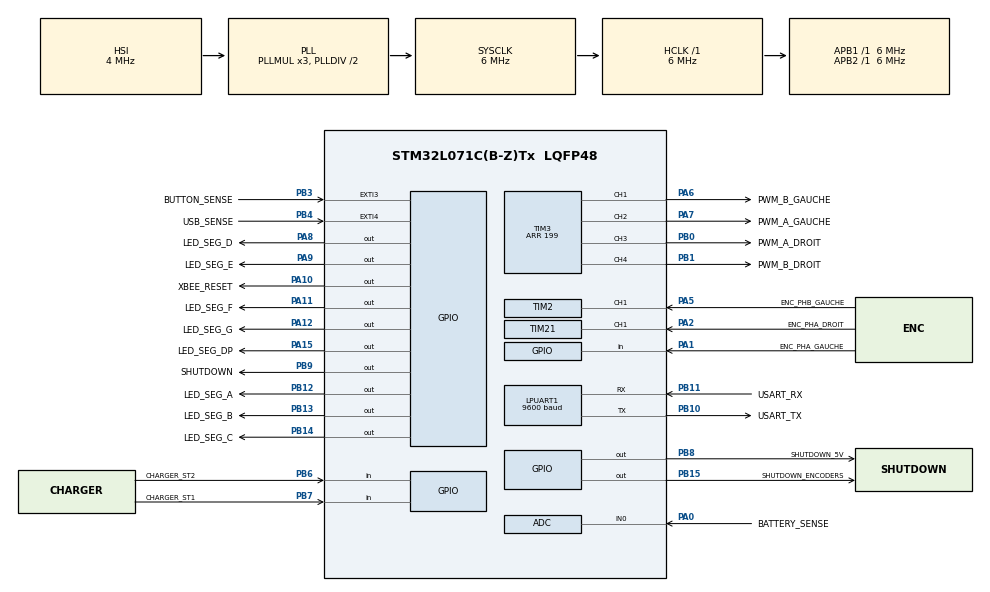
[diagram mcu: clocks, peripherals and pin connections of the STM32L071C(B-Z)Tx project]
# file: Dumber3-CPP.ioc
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ADC.Resolution=ADC_RESOLUTION_8B
ADC.SamplingTime=ADC_SAMPLETIME_160CYCLES_5
FREERTOS.INCLUDE_pcTaskGetTaskName=1
FREERTOS.INCLUDE_xEventGroupSetBitFromISR=1
FREERTOS.INCLUDE_xTaskAbortDelay=1
FREERTOS.INCLUDE_xTaskGetCurrentTaskHandle=1
FREERTOS.INCLUDE_xTaskGetHandle=1
FREERTOS.Tasks01=defaultTask,24,128,StartDefaultTask,Default,NULL,Dynamic,NULL,NULL
FREERTOS.configMAX_TASK_NAME_LEN=25
FREERTOS.configTICK_RATE_HZ=1000
FREERTOS.configTIMER_TASK_PRIORITY=3
FREERTOS.configTOTAL_HEAP_SIZE=1024
FREERTOS.configUSE_NEWLIB_REENTRANT=1
FREERTOS.configUSE_TICKLESS_IDLE=1
LPUART1.BaudRate=9600
LPUART1.DMADisableonRxErrorParam=UART_ADVFEATURE_DMA_DISABLEONRXERROR
LPUART1.WordLength=UART_WORDLENGTH_8B
Mcu.Family=STM32L0
Mcu.Name=STM32L071C(B-Z)Tx
Mcu.Package=LQFP48
NVIC.ADC1_COMP_IRQn=true\:3\:0\:false\:false\:true\:true\:true\:true\:true
NVIC.EXTI2_3_IRQn=true\:3\:0\:false\:false\:true\:true\:true\:true\:true
NVIC.EXTI4_15_IRQn=true\:3\:0\:false\:false\:true\:true\:true\:true\:true
NVIC.LPUART1_IRQn=true\:3\:0\:true\:false\:true\:true\:true\:true\:true
NVIC.TIM21_IRQn=true\:1\:0\:true\:false\:true\:false\:true\:true\:true
NVIC.TIM2_IRQn=true\:1\:0\:true\:false\:true\:false\:true\:true\:true
NVIC.TIM6_IRQn=true\:3\:0\:true\:false\:true\:false\:false\:true\:true
NVIC.TimeBase=TIM6_IRQn
NVIC.TimeBaseIP=TIM6
PA0.GPIO_Label=BATTERY_SENSE
PA0.Mode=IN0
PA0.Signal=ADC_IN0
PA1.GPIO_Label=ENC_PHA_GAUCHE
PA1.Signal=GPIO_Input
PA10.GPIO_Label=XBEE_RESET
PA10.PinState=GPIO_PIN_RESET
PA10.Signal=GPIO_Output
PA11.GPIO_Label=LED_SEG_F
PA11.Signal=GPIO_Output
PA12.GPIO_Label=LED_SEG_G
PA12.Signal=GPIO_Output
PA13.Mode=Serial_Wire
PA13.Signal=SYS_SWDIO
PA14.Mode=Serial_Wire
PA14.Signal=SYS_SWCLK
PA15.GPIO_Label=LED_SEG_DP
PA15.Signal=GPIO_Output
PA2.GPIO_Label=ENC_PHA_DROIT
PA2.Signal=S_TIM21_CH1
PA5.GPIO_Label=ENC_PHB_GAUCHE
PA5.Signal=S_TIM2_CH1
PA6.GPIO_Label=PWM_B_GAUCHE
PA6.Signal=S_TIM3_CH1
PA7.GPIO_Label=PWM_A_GAUCHE
PA7.Signal=S_TIM3_CH2
PA8.GPIO_Label=LED_SEG_D
PA8.Signal=GPIO_Output
PA9.GPIO_Label=LED_SEG_E
PA9.Signal=GPIO_Output
PB0.GPIO_Label=PWM_A_DROIT
PB0.GPIO_Speed=GPIO_SPEED_FREQ_LOW
PB0.Signal=S_TIM3_CH3
PB1.GPIO_Label=PWM_B_DROIT
PB1.GPIO_Speed=GPIO_SPEED_FREQ_LOW
PB1.Signal=S_TIM3_CH4
PB10.GPIO_Label=USART_TX
PB10.GPIO_Speed=GPIO_SPEED_FREQ_LOW
PB10.Mode=Asynchronous
PB10.Signal=LPUART1_TX
PB11.GPIO_Label=USART_RX
PB11.GPIO_Speed=GPIO_SPEED_FREQ_LOW
PB11.Mode=Asynchronous
PB11.Signal=LPUART1_RX
PB12.GPIO_Label=LED_SEG_A
PB12.GPIO_Speed=GPIO_SPEED_FREQ_LOW
PB12.PinState=GPIO_PIN_RESET
PB12.Signal=GPIO_Output
PB13.GPIO_Label=LED_SEG_B
PB13.GPIO_Speed=GPIO_SPEED_FREQ_LOW
PB13.Signal=GPIO_Output
PB14.GPIO_Label=LED_SEG_C
PB14.GPIO_Speed=GPIO_SPEED_FREQ_LOW
PB14.Signal=GPIO_Output
PB15.GPIO_Label=SHUTDOWN_ENCODERS
PB15.PinState=GPIO_PIN_SET
PB15.Signal=GPIO_Output
PB3.GPIO_Label=BUTTON_SENSE
PB3.GPIO_ModeDefaultEXTI=GPIO_MODE_IT_FALLING
PB3.Signal=GPXTI3
PB4.GPIO_Label=USB_SENSE
PB4.GPIO_ModeDefaultEXTI=GPIO_MODE_IT_RISING_FALLING
PB4.Signal=GPXTI4
PB6.GPIO_Label=CHARGER_ST2
PB6.Signal=GPIO_Input
PB7.GPIO_Label=CHARGER_ST1
PB7.Signal=GPIO_Input
PB8.GPIO_Label=SHUTDOWN_5V
PB8.Signal=GPIO_Output
PB9.GPIO_Label=SHUTDOWN
PB9.GPIO_ModeDefaultOutputPP=GPIO_MODE_OUTPUT_OD
PB9.PinState=GPIO_PIN_SET
PB9.Signal=GPIO_Output
ProjectManager.HeapSize=0x0
ProjectManager.StackSize=0x200
ProjectManager.TargetToolchain=STM32CubeIDE
RCC.ADCFreq_Value=4000000
RCC.AHBFreq_Value=6000000
RCC.APB1Freq_Value=6000000
RCC.APB1TimFreq_Value=6000000
RCC.APB2Freq_Value=6000000
RCC.APB2TimFreq_Value=6000000
RCC.HCLKFreq_Value=6000000
RCC.HSE_VALUE=8000000
RCC.HSI16_VALUE=16000000
RCC.HSIRCDiv=4
RCC.HSI_VALUE=4000000
RCC.LSE_VALUE=32768
RCC.MSI_VALUE=2097000
RCC.SYSCLKFreq_VALUE=6000000
RCC.SYSCLKSource=RCC_SYSCLKSOURCE_PLLCLK
RCC.VCOOutputFreq_Value=12000000
SH.S_TIM21_CH1.0=TIM21_CH1,PWM_Input_1
SH.S_TIM2_CH1.0=TIM2_CH1,PWM_Input_1
SH.S_TIM3_CH1.0=TIM3_CH1,PWM Generation1 CH1
SH.S_TIM3_CH2.0=TIM3_CH2,PWM Generation2 CH2
SH.S_TIM3_CH3.0=TIM3_CH3,PWM Generation3 CH3
SH.S_TIM3_CH4.0=TIM3_CH4,PWM Generation4 CH4
TIM2.ICFilter_1=3
TIM2.ICFilter_2=3
TIM2.Prescaler=0
TIM21.ICFilter_1=3
TIM21.ICFilter_2=3
TIM21.Prescaler=0
TIM3.Channel-PWM\ Generation1\ CH1=TIM_CHANNEL_1
TIM3.Channel-PWM\ Generation2\ CH2=TIM_CHANNEL_2
TIM3.Channel-PWM\ Generation3\ CH3=TIM_CHANNEL_3
TIM3.Channel-PWM\ Generation4\ CH4=TIM_CHANNEL_4
TIM3.Period=199
VP_FREERTOS_VS_CMSIS_V2.Mode=CMSIS_V2
VP_SYS_VS_tim6.Mode=TIM6
VP_TIM21_VS_ClockSourceINT.Mode=Internal
VP_TIM2_VS_ClockSourceINT.Mode=Internal
VP_TIM3_VS_ClockSourceINT.Mode=Internal
board=custom

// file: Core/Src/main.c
/* USER CODE BEGIN Header */
/**
  ******************************************************************************
  * @file           : main.c
  * @brief          : Main program body
  ******************************************************************************
  * @attention
  *
  * Copyright (c) 2026 STMicroelectronics.
  * All rights reserved.
  *
  * This software is licensed under terms that can be found in the LICENSE file
  * in the root directory of this software component.
  * If no LICENSE file comes with this software, it is provided AS-IS.
  *
  ******************************************************************************
  */
/* USER CODE END Header */
#include "main.h"
#include "cmsis_os.h"

/* USER CODE BEGIN Includes */
#include "app_main.h"
/* USER CODE END Includes */

ADC_HandleTypeDef hadc;

UART_HandleTypeDef hlpuart1;

TIM_HandleTypeDef htim2;
TIM_HandleTypeDef htim3;
TIM_HandleTypeDef htim21;

/* Definitions for defaultTask */
osThreadId_t defaultTaskHandle;
const osThreadAttr_t defaultTask_attributes = {
  .name = "defaultTask",
  .stack_size = 128 * 4,
  .priority = (osPriority_t) osPriorityNormal,
};

void SystemClock_Config(void);
static void MX_GPIO_Init(void);
static void MX_LPUART1_UART_Init(void);
static void MX_TIM2_Init(void);
static void MX_TIM3_Init(void);
static void MX_TIM21_Init(void);
static void MX_ADC_Init(void);
void StartDefaultTask(void *argument);

int main(void)
{

  /* MCU Configuration--------------------------------------------------------*/

  /* Reset of all peripherals, Initializes the Flash interface and the Systick. */
  HAL_Init();

  /* Configure the system clock */
  SystemClock_Config();

  /* Initialize all configured peripherals */
  MX_GPIO_Init();
  MX_LPUART1_UART_Init();
  MX_TIM2_Init();
  MX_TIM3_Init();
  MX_TIM21_Init();
  MX_ADC_Init();

  /* Init scheduler */
  osKernelInitialize();

  APPLICATION_Start();

  /* Create the thread(s) */
  /* creation of defaultTask */
  defaultTaskHandle = osThreadNew(StartDefaultTask, NULL, &defaultTask_attributes);

  /* Start scheduler */
  osKernelStart();

  /* We should never get here as control is now taken by the scheduler */

  /* Infinite loop */
  while (1)
  {

  }
}

void SystemClock_Config(void)
{
  RCC_OscInitTypeDef RCC_OscInitStruct = {0};
  RCC_ClkInitTypeDef RCC_ClkInitStruct = {0};
  RCC_PeriphCLKInitTypeDef PeriphClkInit = {0};

  /** Configure the main internal regulator output voltage
  */
  __HAL_PWR_VOLTAGESCALING_CONFIG(PWR_REGULATOR_VOLTAGE_SCALE1);

  /** Initializes the RCC Oscillators according to the specified parameters
  * in the RCC_OscInitTypeDef structure.
  */
  RCC_OscInitStruct.OscillatorType = RCC_OSCILLATORTYPE_HSI;
  RCC_OscInitStruct.HSIState = RCC_HSI_DIV4;
  RCC_OscInitStruct.HSICalibrationValue = RCC_HSICALIBRATION_DEFAULT;
  RCC_OscInitStruct.PLL.PLLState = RCC_PLL_ON;
  RCC_OscInitStruct.PLL.PLLSource = RCC_PLLSOURCE_HSI;
  RCC_OscInitStruct.PLL.PLLMUL = RCC_PLLMUL_3;
  RCC_OscInitStruct.PLL.PLLDIV = RCC_PLLDIV_2;
  if (HAL_RCC_OscConfig(&RCC_OscInitStruct) != HAL_OK)
  {
    Error_Handler();
  }

  /** Initializes the CPU, AHB and APB buses clocks
  */
  RCC_ClkInitStruct.ClockType = RCC_CLOCKTYPE_HCLK|RCC_CLOCKTYPE_SYSCLK
                              |RCC_CLOCKTYPE_PCLK1|RCC_CLOCKTYPE_PCLK2;
  RCC_ClkInitStruct.SYSCLKSource = RCC_SYSCLKSOURCE_PLLCLK;
  RCC_ClkInitStruct.AHBCLKDivider = RCC_SYSCLK_DIV1;
  RCC_ClkInitStruct.APB1CLKDivider = RCC_HCLK_DIV1;
  RCC_ClkInitStruct.APB2CLKDivider = RCC_HCLK_DIV1;

  if (HAL_RCC_ClockConfig(&RCC_ClkInitStruct, FLASH_LATENCY_0) != HAL_OK)
  {
    Error_Handler();
  }
  PeriphClkInit.PeriphClockSelection = RCC_PERIPHCLK_LPUART1;
  PeriphClkInit.Lpuart1ClockSelection = RCC_LPUART1CLKSOURCE_PCLK1;
  if (HAL_RCCEx_PeriphCLKConfig(&PeriphClkInit) != HAL_OK)
  {
    Error_Handler();
  }
}

static void MX_ADC_Init(void)
{

  ADC_ChannelConfTypeDef sConfig = {0};

  /** Configure the global features of the ADC (Clock, Resolution, Data Alignment and number of conversion)
  */
  hadc.Instance = ADC1;
  hadc.Init.OversamplingMode = DISABLE;
  hadc.Init.ClockPrescaler = ADC_CLOCK_SYNC_PCLK_DIV1;
  hadc.Init.Resolution = ADC_RESOLUTION_8B;
  hadc.Init.SamplingTime = ADC_SAMPLETIME_160CYCLES_5;
  hadc.Init.ScanConvMode = ADC_SCAN_DIRECTION_FORWARD;
  hadc.Init.DataAlign = ADC_DATAALIGN_RIGHT;
  hadc.Init.ContinuousConvMode = DISABLE;
  hadc.Init.DiscontinuousConvMode = DISABLE;
  hadc.Init.ExternalTrigConvEdge = ADC_EXTERNALTRIGCONVEDGE_NONE;
  hadc.Init.ExternalTrigConv = ADC_SOFTWARE_START;
  hadc.Init.DMAContinuousRequests = DISABLE;
  hadc.Init.EOCSelection = ADC_EOC_SINGLE_CONV;
  hadc.Init.Overrun = ADC_OVR_DATA_PRESERVED;
  hadc.Init.LowPowerAutoWait = DISABLE;
  hadc.Init.LowPowerFrequencyMode = DISABLE;
  hadc.Init.LowPowerAutoPowerOff = DISABLE;
  if (HAL_ADC_Init(&hadc) != HAL_OK)
  {
    Error_Handler();
  }

  /** Configure for the selected ADC regular channel to be converted.
  */
  sConfig.Channel = ADC_CHANNEL_0;
  sConfig.Rank = ADC_RANK_CHANNEL_NUMBER;
  if (HAL_ADC_ConfigChannel(&hadc, &sConfig) != HAL_OK)
  {
    Error_Handler();
  }

}

static void MX_LPUART1_UART_Init(void)
{

  hlpuart1.Instance = LPUART1;
  hlpuart1.Init.BaudRate = 9600;
  hlpuart1.Init.WordLength = UART_WORDLENGTH_8B;
  hlpuart1.Init.StopBits = UART_STOPBITS_1;
  hlpuart1.Init.Parity = UART_PARITY_NONE;
  hlpuart1.Init.Mode = UART_MODE_TX_RX;
  hlpuart1.Init.HwFlowCtl = UART_HWCONTROL_NONE;
  hlpuart1.Init.OneBitSampling = UART_ONE_BIT_SAMPLE_DISABLE;
  hlpuart1.AdvancedInit.AdvFeatureInit = UART_ADVFEATURE_DMADISABLEONERROR_INIT;
  hlpuart1.AdvancedInit.DMADisableonRxError = UART_ADVFEATURE_DMA_DISABLEONRXERROR;
  if (HAL_UART_Init(&hlpuart1) != HAL_OK)
  {
    Error_Handler();
  }

}

static void MX_TIM2_Init(void)
{

  TIM_ClockConfigTypeDef sClockSourceConfig = {0};
  TIM_SlaveConfigTypeDef sSlaveConfig = {0};
  TIM_IC_InitTypeDef sConfigIC = {0};
  TIM_MasterConfigTypeDef sMasterConfig = {0};

  htim2.Instance = TIM2;
  htim2.Init.Prescaler = 0;
  htim2.Init.CounterMode = TIM_COUNTERMODE_UP;
  htim2.Init.Period = 65535;
  htim2.Init.ClockDivision = TIM_CLOCKDIVISION_DIV1;
  htim2.Init.AutoReloadPreload = TIM_AUTORELOAD_PRELOAD_DISABLE;
  if (HAL_TIM_Base_Init(&htim2) != HAL_OK)
  {
    Error_Handler();
  }
  sClockSourceConfig.ClockSource = TIM_CLOCKSOURCE_INTERNAL;
  if (HAL_TIM_ConfigClockSource(&htim2, &sClockSourceConfig) != HAL_OK)
  {
    Error_Handler();
  }
  if (HAL_TIM_IC_Init(&htim2) != HAL_OK)
  {
    Error_Handler();
  }
  sSlaveConfig.SlaveMode = TIM_SLAVEMODE_RESET;
  sSlaveConfig.InputTrigger = TIM_TS_TI1FP1;
  sSlaveConfig.TriggerPolarity = TIM_INPUTCHANNELPOLARITY_RISING;
  sSlaveConfig.TriggerPrescaler = TIM_ICPSC_DIV1;
  sSlaveConfig.TriggerFilter = 3;
  if (HAL_TIM_SlaveConfigSynchro(&htim2, &sSlaveConfig) != HAL_OK)
  {
    Error_Handler();
  }
  sConfigIC.ICPolarity = TIM_INPUTCHANNELPOLARITY_RISING;
  sConfigIC.ICSelection = TIM_ICSELECTION_DIRECTTI;
  sConfigIC.ICPrescaler = TIM_ICPSC_DIV1;
  sConfigIC.ICFilter = 3;
  if (HAL_TIM_IC_ConfigChannel(&htim2, &sConfigIC, TIM_CHANNEL_1) != HAL_OK)
  {
    Error_Handler();
  }
  sConfigIC.ICPolarity = TIM_INPUTCHANNELPOLARITY_FALLING;
  sConfigIC.ICSelection = TIM_ICSELECTION_INDIRECTTI;
  if (HAL_TIM_IC_ConfigChannel(&htim2, &sConfigIC, TIM_CHANNEL_2) != HAL_OK)
  {
    Error_Handler();
  }
  sMasterConfig.MasterOutputTrigger = TIM_TRGO_RESET;
  sMasterConfig.MasterSlaveMode = TIM_MASTERSLAVEMODE_DISABLE;
  if (HAL_TIMEx_MasterConfigSynchronization(&htim2, &sMasterConfig) != HAL_OK)
  {
    Error_Handler();
  }

}

static void MX_TIM3_Init(void)
{

  TIM_ClockConfigTypeDef sClockSourceConfig = {0};
  TIM_MasterConfigTypeDef sMasterConfig = {0};
  TIM_OC_InitTypeDef sConfigOC = {0};

  htim3.Instance = TIM3;
  htim3.Init.Prescaler = 0;
  htim3.Init.CounterMode = TIM_COUNTERMODE_UP;
  htim3.Init.Period = 199;
  htim3.Init.ClockDivision = TIM_CLOCKDIVISION_DIV1;
  htim3.Init.AutoReloadPreload = TIM_AUTORELOAD_PRELOAD_DISABLE;
  if (HAL_TIM_Base_Init(&htim3) != HAL_OK)
  {
    Error_Handler();
  }
  sClockSourceConfig.ClockSource = TIM_CLOCKSOURCE_INTERNAL;
  if (HAL_TIM_ConfigClockSource(&htim3, &sClockSourceConfig) != HAL_OK)
  {
    Error_Handler();
  }
  if (HAL_TIM_PWM_Init(&htim3) != HAL_OK)
  {
    Error_Handler();
  }
  sMasterConfig.MasterOutputTrigger = TIM_TRGO_RESET;
  sMasterConfig.MasterSlaveMode = TIM_MASTERSLAVEMODE_DISABLE;
  if (HAL_TIMEx_MasterConfigSynchronization(&htim3, &sMasterConfig) != HAL_OK)
  {
    Error_Handler();
  }
  sConfigOC.OCMode = TIM_OCMODE_PWM1;
  sConfigOC.Pulse = 0;
  sConfigOC.OCPolarity = TIM_OCPOLARITY_HIGH;
  sConfigOC.OCFastMode = TIM_OCFAST_DISABLE;
  if (HAL_TIM_PWM_ConfigChannel(&htim3, &sConfigOC, TIM_CHANNEL_1) != HAL_OK)
  {
    Error_Handler();
  }
  if (HAL_TIMEx_RemapConfig(&htim3, TIM3_TI1_GPIO) != HAL_OK)
  {
    Error_Handler();
  }
  if (HAL_TIM_PWM_ConfigChannel(&htim3, &sConfigOC, TIM_CHANNEL_2) != HAL_OK)
  {
    Error_Handler();
  }
  if (HAL_TIM_PWM_ConfigChannel(&htim3, &sConfigOC, TIM_CHANNEL_3) != HAL_OK)
  {
    Error_Handler();
  }
  if (HAL_TIM_PWM_ConfigChannel(&htim3, &sConfigOC, TIM_CHANNEL_4) != HAL_OK)
  {
    Error_Handler();
  }
  HAL_TIM_MspPostInit(&htim3);

}

static void MX_TIM21_Init(void)
{

  TIM_ClockConfigTypeDef sClockSourceConfig = {0};
  TIM_SlaveConfigTypeDef sSlaveConfig = {0};
  TIM_IC_InitTypeDef sConfigIC = {0};
  TIM_MasterConfigTypeDef sMasterConfig = {0};

  htim21.Instance = TIM21;
  htim21.Init.Prescaler = 0;
  htim21.Init.CounterMode = TIM_COUNTERMODE_UP;
  htim21.Init.Period = 65535;
  htim21.Init.ClockDivision = TIM_CLOCKDIVISION_DIV1;
  htim21.Init.AutoReloadPreload = TIM_AUTORELOAD_PRELOAD_DISABLE;
  if (HAL_TIM_Base_Init(&htim21) != HAL_OK)
  {
    Error_Handler();
  }
  sClockSourceConfig.ClockSource = TIM_CLOCKSOURCE_INTERNAL;
  if (HAL_TIM_ConfigClockSource(&htim21, &sClockSourceConfig) != HAL_OK)
  {
    Error_Handler();
  }
  if (HAL_TIM_IC_Init(&htim21) != HAL_OK)
  {
    Error_Handler();
  }
  sSlaveConfig.SlaveMode = TIM_SLAVEMODE_RESET;
  sSlaveConfig.InputTrigger = TIM_TS_TI1FP1;
  sSlaveConfig.TriggerPolarity = TIM_INPUTCHANNELPOLARITY_RISING;
  sSlaveConfig.TriggerPrescaler = TIM_ICPSC_DIV1;
  sSlaveConfig.TriggerFilter = 3;
  if (HAL_TIM_SlaveConfigSynchro(&htim21, &sSlaveConfig) != HAL_OK)
  {
    Error_Handler();
  }
  sConfigIC.ICPolarity = TIM_INPUTCHANNELPOLARITY_RISING;
  sConfigIC.ICSelection = TIM_ICSELECTION_DIRECTTI;
  sConfigIC.ICPrescaler = TIM_ICPSC_DIV1;
  sConfigIC.ICFilter = 3;
  if (HAL_TIM_IC_ConfigChannel(&htim21, &sConfigIC, TIM_CHANNEL_1) != HAL_OK)
  {
    Error_Handler();
  }
  sConfigIC.ICPolarity = TIM_INPUTCHANNELPOLARITY_FALLING;
  sConfigIC.ICSelection = TIM_ICSELECTION_INDIRECTTI;
  if (HAL_TIM_IC_ConfigChannel(&htim21, &sConfigIC, TIM_CHANNEL_2) != HAL_OK)
  {
    Error_Handler();
  }
  sMasterConfig.MasterOutputTrigger = TIM_TRGO_RESET;
  sMasterConfig.MasterSlaveMode = TIM_MASTERSLAVEMODE_DISABLE;
  if (HAL_TIMEx_MasterConfigSynchronization(&htim21, &sMasterConfig) != HAL_OK)
  {
    Error_Handler();
  }

}

static void MX_GPIO_Init(void)
{
  GPIO_InitTypeDef GPIO_InitStruct = {0};

  /* GPIO Ports Clock Enable */
  __HAL_RCC_GPIOA_CLK_ENABLE();
  __HAL_RCC_GPIOB_CLK_ENABLE();

  /*Configure GPIO pin Output Level */
  HAL_GPIO_WritePin(GPIOB, LED_SEG_A_Pin|LED_SEG_B_Pin|LED_SEG_C_Pin|SHUTDOWN_5V_Pin, GPIO_PIN_RESET);

  /*Configure GPIO pin Output Level */
  HAL_GPIO_WritePin(GPIOB, SHUTDOWN_ENCODERS_Pin|SHUTDOWN_Pin, GPIO_PIN_SET);

  /*Configure GPIO pin Output Level */
  HAL_GPIO_WritePin(GPIOA, LED_SEG_D_Pin|LED_SEG_E_Pin|XBEE_RESET_Pin|LED_SEG_F_Pin
                          |LED_SEG_G_Pin|LED_SEG_DP_Pin, GPIO_PIN_RESET);

  /*Configure GPIO pin : ENC_PHA_GAUCHE_Pin */
  GPIO_InitStruct.Pin = ENC_PHA_GAUCHE_Pin;
  GPIO_InitStruct.Mode = GPIO_MODE_INPUT;
  GPIO_InitStruct.Pull = GPIO_NOPULL;
  HAL_GPIO_Init(ENC_PHA_GAUCHE_GPIO_Port, &GPIO_InitStruct);

  /*Configure GPIO pins : LED_SEG_A_Pin LED_SEG_B_Pin LED_SEG_C_Pin SHUTDOWN_ENCODERS_Pin
                           SHUTDOWN_5V_Pin */
  GPIO_InitStruct.Pin = LED_SEG_A_Pin|LED_SEG_B_Pin|LED_SEG_C_Pin|SHUTDOWN_ENCODERS_Pin
                          |SHUTDOWN_5V_Pin;
  GPIO_InitStruct.Mode = GPIO_MODE_OUTPUT_PP;
  GPIO_InitStruct.Pull = GPIO_NOPULL;
  GPIO_InitStruct.Speed = GPIO_SPEED_FREQ_LOW;
  HAL_GPIO_Init(GPIOB, &GPIO_InitStruct);

  /*Configure GPIO pins : LED_SEG_D_Pin LED_SEG_E_Pin XBEE_RESET_Pin LED_SEG_F_Pin
                           LED_SEG_G_Pin LED_SEG_DP_Pin */
  GPIO_InitStruct.Pin = LED_SEG_D_Pin|LED_SEG_E_Pin|XBEE_RESET_Pin|LED_SEG_F_Pin
                          |LED_SEG_G_Pin|LED_SEG_DP_Pin;
  GPIO_InitStruct.Mode = GPIO_MODE_OUTPUT_PP;
  GPIO_InitStruct.Pull = GPIO_NOPULL;
  GPIO_InitStruct.Speed = GPIO_SPEED_FREQ_LOW;
  HAL_GPIO_Init(GPIOA, &GPIO_InitStruct);

  /*Configure GPIO pin : BUTTON_SENSE_Pin */
  GPIO_InitStruct.Pin = BUTTON_SENSE_Pin;
  GPIO_InitStruct.Mode = GPIO_MODE_IT_FALLING;
  GPIO_InitStruct.Pull = GPIO_NOPULL;
  HAL_GPIO_Init(BUTTON_SENSE_GPIO_Port, &GPIO_InitStruct);

  /*Configure GPIO pin : USB_SENSE_Pin */
  GPIO_InitStruct.Pin = USB_SENSE_Pin;
  GPIO_InitStruct.Mode = GPIO_MODE_IT_RISING_FALLING;
  GPIO_InitStruct.Pull = GPIO_NOPULL;
  HAL_GPIO_Init(USB_SENSE_GPIO_Port, &GPIO_InitStruct);

  /*Configure GPIO pins : CHARGER_ST2_Pin CHARGER_ST1_Pin */
  GPIO_InitStruct.Pin = CHARGER_ST2_Pin|CHARGER_ST1_Pin;
  GPIO_InitStruct.Mode = GPIO_MODE_INPUT;
  GPIO_InitStruct.Pull = GPIO_NOPULL;
  HAL_GPIO_Init(GPIOB, &GPIO_InitStruct);

  /*Configure GPIO pin : SHUTDOWN_Pin */
  GPIO_InitStruct.Pin = SHUTDOWN_Pin;
  GPIO_InitStruct.Mode = GPIO_MODE_OUTPUT_OD;
  GPIO_InitStruct.Pull = GPIO_NOPULL;
  GPIO_InitStruct.Speed = GPIO_SPEED_FREQ_LOW;
  HAL_GPIO_Init(SHUTDOWN_GPIO_Port, &GPIO_InitStruct);

  /* EXTI interrupt init*/
  HAL_NVIC_SetPriority(EXTI2_3_IRQn, 3, 0);
  HAL_NVIC_EnableIRQ(EXTI2_3_IRQn);

  HAL_NVIC_SetPriority(EXTI4_15_IRQn, 3, 0);
  HAL_NVIC_EnableIRQ(EXTI4_15_IRQn);

}

void StartDefaultTask(void *argument)
{
  for(;;)
  {
    osDelay(1);
  }
}

void HAL_TIM_PeriodElapsedCallback(TIM_HandleTypeDef *htim)
{
  if (htim->Instance == TIM6)
  {
    HAL_IncTick();
  }
}

void Error_Handler(void)
{
  __disable_irq();
  while (1)
  {
  }
}
